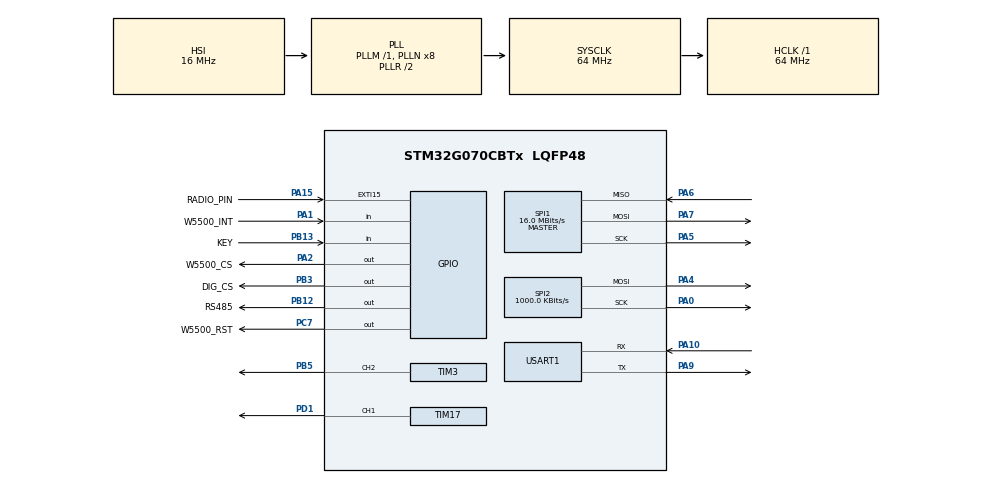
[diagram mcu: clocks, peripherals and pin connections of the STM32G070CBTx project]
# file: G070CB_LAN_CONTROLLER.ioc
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FREERTOS.BinarySemaphores01=SemSaveSettings,Static,mySemSaveSettingsControlBlock
FREERTOS.MEMORY_ALLOCATION=1
FREERTOS.Queues01=Periods,30,uint32_t,0,Static,PeriodsBuffer,PeriodsControlBlock;MQTT_Messages,10,MQTT_Packet,0,Static,MQTT_MessagesBuffer,MQTT_MessagesControlBlock;logQueue,200,unsigned char,0,Static,myQueue03Buffer,myQueue03ControlBlock;modbusQueue,5,uint64_t,0,Static,modbusQueue04Buffer,myQueue04ControlBlock
FREERTOS.Tasks01=defaultTask,-1,300,StartDefaultTask,As weak,NULL,Static,defaultTaskBuffer,defaultTaskControlBlock;LanTask,-1,400,StartLanTask,As weak,NULL,Static,LanTaskBuffer,LanTaskControlBlock;RadioReceiver,-3,200,StartRadioReceiver,As weak,NULL,Static,RadioReceiverBuffer,RadioReceiverControlBlock;ModBus,-1,300,modbus,As weak,NULL,Static,myTask04Buffer,myTask04ControlBlock;SaveSettings,3,128,SaveSettingsTask,As weak,NULL,Static,myTask05Buffer,myTask05ControlBlock
FREERTOS.Timers01=LED_INDICATION,led_indication,osTimerPeriodic,As weak,NULL,Static,LED_INDICATIONControlBlock;everySecond,everySecondCallback,osTimerPeriodic,As weak,NULL,Static,everySecondControlBlock;modBusTimer,ModBusCallback,osTimerPeriodic,As weak,NULL,Static,myTimer03ControlBlock
FREERTOS.configTOTAL_HEAP_SIZE=7000
FREERTOS.configUSE_NEWLIB_REENTRANT=1
FREERTOS.configUSE_TIMERS=1
FREERTOS.configUSE_TRACE_FACILITY=1
IWDG.Prescaler=IWDG_PRESCALER_256
Mcu.Family=STM32G0
Mcu.Name=STM32G070CBTx
Mcu.Package=LQFP48
NVIC.EXTI4_15_IRQn=true\:3\:0\:true\:false\:true\:false\:true\:true
NVIC.SPI1_IRQn=true\:3\:0\:false\:false\:true\:true\:true\:true
NVIC.TIM6_IRQn=true\:3\:0\:false\:false\:true\:false\:false\:true
NVIC.TimeBase=TIM6_IRQn
NVIC.TimeBaseIP=TIM6
PA0.Mode=TX_Only_Simplex_Unidirect_Master
PA0.Signal=SPI2_SCK
PA1.GPIO_Label=W5500_INT
PA1.Signal=GPIO_Input
PA10.Mode=Asynchronous
PA10.Signal=USART1_RX
PA13.Mode=Serial_Wire
PA13.Signal=SYS_SWDIO
PA14-BOOT0.Mode=Serial_Wire
PA14-BOOT0.Signal=SYS_SWCLK
PA15.GPIO_Label=RADIO_PIN
PA15.GPIO_ModeDefaultEXTI=GPIO_MODE_IT_RISING_FALLING
PA15.Signal=GPXTI15
PA2.GPIO_Label=W5500_CS
PA2.Signal=GPIO_Output
PA4.Mode=TX_Only_Simplex_Unidirect_Master
PA4.Signal=SPI2_MOSI
PA5.Mode=Full_Duplex_Master
PA5.Signal=SPI1_SCK
PA6.Mode=Full_Duplex_Master
PA6.Signal=SPI1_MISO
PA7.Mode=Full_Duplex_Master
PA7.Signal=SPI1_MOSI
PA9.Mode=Asynchronous
PA9.Signal=USART1_TX
PB12.GPIO_Label=RS485
PB12.Signal=GPIO_Output
PB13.GPIO_Label=KEY
PB13.Signal=GPIO_Input
PB3.GPIO_Label=DIG_CS
PB3.GPIO_Speed=GPIO_SPEED_FREQ_HIGH
PB3.PinState=GPIO_PIN_SET
PB3.Signal=GPIO_Output
PB5.Signal=S_TIM3_CH2
PB8.Signal=USART3_TX
PC7.GPIO_Label=W5500_RST
PC7.Signal=GPIO_Output
PD1.Signal=S_TIM17_CH1
ProjectManager.HeapSize=0x400
ProjectManager.StackSize=0x400
ProjectManager.TargetToolchain=STM32CubeIDE
RCC.ADCFreq_Value=64000000
RCC.AHBFreq_Value=64000000
RCC.CortexFreq_Value=64000000
RCC.EXTERNAL_CLOCK_VALUE=48000
RCC.HCLKFreq_Value=64000000
RCC.HSE_VALUE=8000000
RCC.HSI_VALUE=16000000
RCC.LSE_VALUE=32768
RCC.SYSCLKFreq_VALUE=64000000
RCC.SYSCLKSource=RCC_SYSCLKSOURCE_PLLCLK
RCC.VCOOutputFreq_Value=128000000
SH.S_TIM17_CH1.0=TIM17_CH1,PWM Generation1 CH1
SH.S_TIM3_CH2.0=TIM3_CH2,PWM Generation2 CH2
SPI1.BaudRatePrescaler=SPI_BAUDRATEPRESCALER_4
SPI1.CalculateBaudRate=16.0 MBits/s
SPI1.DataSize=SPI_DATASIZE_8BIT
SPI1.Direction=SPI_DIRECTION_2LINES
SPI1.Mode=SPI_MODE_MASTER
SPI1.VirtualType=VM_MASTER
SPI2.BaudRatePrescaler=SPI_BAUDRATEPRESCALER_64
SPI2.CalculateBaudRate=1000.0 KBits/s
SPI2.DataSize=SPI_DATASIZE_8BIT
SPI2.Direction=SPI_DIRECTION_2LINES
SPI2.Mode=SPI_MODE_MASTER
SPI2.VirtualType=VM_MASTER
TIM16.Prescaler=63
TIM17.Channel=TIM_CHANNEL_1
TIM17.OCIdleState_1=TIM_OCIDLESTATE_SET
TIM17.Period=1000
TIM17.Prescaler=10
TIM3.Channel-PWM\ Generation2\ CH2=TIM_CHANNEL_2
TIM3.Period=1000
TIM3.Prescaler=64
TIM3.Pulse-PWM\ Generation2\ CH2=0
USART1.BaudRate=system_settings.uart_speed
USART1.VirtualMode-Asynchronous=VM_ASYNC
VP_FREERTOS_VS_CMSIS_V1.Mode=CMSIS_V1
VP_IWDG_VS_IWDG.Mode=IWDG_Activate
VP_SYS_VS_DBSignals.Mode=DisableDeadBatterySignals
VP_SYS_VS_tim6.Mode=TIM6
VP_TIM16_VS_ClockSourceINT.Mode=Enable_Timer
VP_TIM17_VS_ClockSourceINT.Mode=Enable_Timer
VP_TIM3_VS_ClockSourceINT.Mode=Internal
board=custom

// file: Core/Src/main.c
/* USER CODE BEGIN Header */
/**
  ******************************************************************************
  * @file           : main.c
  * @brief          : Main program body
  ******************************************************************************
  * @attention
  *
  * Copyright (c) 2022 STMicroelectronics.
  * All rights reserved.
  *
  * This software is licensed under terms that can be found in the LICENSE file
  * in the root directory of this software component.
  * If no LICENSE file comes with this software, it is provided AS-IS.
  *
  ******************************************************************************
  */
/* USER CODE END Header */
#include "main.h"
#include "cmsis_os.h"
#include "iwdg.h"
#include "spi.h"
#include "tim.h"
#include "usart.h"
#include "gpio.h"

/* USER CODE BEGIN Includes */
#include "functions.h"
/* USER CODE END Includes */

/* USER CODE BEGIN PV */
extern dev_settings system_settings;
/* USER CODE END PV */

void SystemClock_Config(void);
void MX_FREERTOS_Init(void);

int main(void)
{

  /* MCU Configuration--------------------------------------------------------*/

  /* Reset of all peripherals, Initializes the Flash interface and the Systick. */
  HAL_Init();

  /* USER CODE BEGIN Init */
system_settings.uart_speed =9600;
  /* USER CODE END Init */

  /* Configure the system clock */
  SystemClock_Config();

  /* Initialize all configured peripherals */
  MX_GPIO_Init();
  MX_SPI1_Init();
  MX_SPI2_Init();
  MX_USART1_UART_Init();
  MX_TIM16_Init();
  MX_IWDG_Init();
  MX_TIM3_Init();
  MX_TIM17_Init();
  /* USER CODE BEGIN 2 */

  HAL_TIM_PWM_Start(&htim17, TIM_CHANNEL_1);

  /* USER CODE END 2 */

  /* Call init function for freertos objects (in freertos.c) */
  MX_FREERTOS_Init();
  /* Start scheduler */
  osKernelStart();

  /* We should never get here as control is now taken by the scheduler */
  /* Infinite loop */
  while (1)
  {

  }
}

void SystemClock_Config(void)
{
  RCC_OscInitTypeDef RCC_OscInitStruct = {0};
  RCC_ClkInitTypeDef RCC_ClkInitStruct = {0};

  /** Configure the main internal regulator output voltage
  */
  HAL_PWREx_ControlVoltageScaling(PWR_REGULATOR_VOLTAGE_SCALE1);
  /** Initializes the RCC Oscillators according to the specified parameters
  * in the RCC_OscInitTypeDef structure.
  */
  RCC_OscInitStruct.OscillatorType = RCC_OSCILLATORTYPE_HSI|RCC_OSCILLATORTYPE_LSI;
  RCC_OscInitStruct.HSIState = RCC_HSI_ON;
  RCC_OscInitStruct.HSIDiv = RCC_HSI_DIV1;
  RCC_OscInitStruct.HSICalibrationValue = RCC_HSICALIBRATION_DEFAULT;
  RCC_OscInitStruct.LSIState = RCC_LSI_ON;
  RCC_OscInitStruct.PLL.PLLState = RCC_PLL_ON;
  RCC_OscInitStruct.PLL.PLLSource = RCC_PLLSOURCE_HSI;
  RCC_OscInitStruct.PLL.PLLM = RCC_PLLM_DIV1;
  RCC_OscInitStruct.PLL.PLLN = 8;
  RCC_OscInitStruct.PLL.PLLP = RCC_PLLP_DIV2;
  RCC_OscInitStruct.PLL.PLLR = RCC_PLLR_DIV2;
  if (HAL_RCC_OscConfig(&RCC_OscInitStruct) != HAL_OK)
  {
    Error_Handler();
  }
  /** Initializes the CPU, AHB and APB buses clocks
  */
  RCC_ClkInitStruct.ClockType = RCC_CLOCKTYPE_HCLK|RCC_CLOCKTYPE_SYSCLK
                              |RCC_CLOCKTYPE_PCLK1;
  RCC_ClkInitStruct.SYSCLKSource = RCC_SYSCLKSOURCE_PLLCLK;
  RCC_ClkInitStruct.AHBCLKDivider = RCC_SYSCLK_DIV1;
  RCC_ClkInitStruct.APB1CLKDivider = RCC_HCLK_DIV1;

  if (HAL_RCC_ClockConfig(&RCC_ClkInitStruct, FLASH_LATENCY_2) != HAL_OK)
  {
    Error_Handler();
  }
}

void HAL_TIM_PeriodElapsedCallback(TIM_HandleTypeDef *htim)
{
  if (htim->Instance == TIM6) {
    HAL_IncTick();
  }
}

void Error_Handler(void)
{
  __disable_irq();
  while (1)
  {
  }
}

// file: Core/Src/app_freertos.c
/* USER CODE BEGIN Header */
/**
  ******************************************************************************
  * File Name          : app_freertos.c
  * Description        : Code for freertos applications
  ******************************************************************************
  * @attention
  *
  * Copyright (c) 2022 STMicroelectronics.
  * All rights reserved.
  *
  * This software is licensed under terms that can be found in the LICENSE file
  * in the root directory of this software component.
  * If no LICENSE file comes with this software, it is provided AS-IS.
  *
  ******************************************************************************
  */
/* USER CODE END Header */

#include "FreeRTOS.h"
#include "task.h"
#include "main.h"
#include "cmsis_os.h"

/* USER CODE BEGIN Includes */
#include "common.h"
/* USER CODE END Includes */

osThreadId defaultTaskHandle;
uint32_t defaultTaskBuffer[ 300 ];
osStaticThreadDef_t defaultTaskControlBlock;
osThreadId LanTaskHandle;
uint32_t LanTaskBuffer[ 400 ];
osStaticThreadDef_t LanTaskControlBlock;
osThreadId RadioReceiverHandle;
uint32_t RadioReceiverBuffer[ 200 ];
osStaticThreadDef_t RadioReceiverControlBlock;
osThreadId ModBusHandle;
uint32_t myTask04Buffer[ 300 ];
osStaticThreadDef_t myTask04ControlBlock;
osThreadId SaveSettingsHandle;
uint32_t myTask05Buffer[ 128 ];
osStaticThreadDef_t myTask05ControlBlock;
osMessageQId PeriodsHandle;
uint8_t PeriodsBuffer[ 30 * sizeof( uint32_t ) ];
osStaticMessageQDef_t PeriodsControlBlock;
osMessageQId MQTT_MessagesHandle;
uint8_t MQTT_MessagesBuffer[ 10 * sizeof( MQTT_Packet ) ];
osStaticMessageQDef_t MQTT_MessagesControlBlock;
osMessageQId logQueueHandle;
uint8_t myQueue03Buffer[ 200 * sizeof( unsigned char ) ];
osStaticMessageQDef_t myQueue03ControlBlock;
osMessageQId modbusQueueHandle;
uint8_t modbusQueue04Buffer[ 5 * sizeof( uint64_t ) ];
osStaticMessageQDef_t myQueue04ControlBlock;
osTimerId LED_INDICATIONHandle;
osStaticTimerDef_t LED_INDICATIONControlBlock;
osTimerId everySecondHandle;
osStaticTimerDef_t everySecondControlBlock;
osTimerId modBusTimerHandle;
osStaticTimerDef_t myTimer03ControlBlock;
osSemaphoreId SemSaveSettingsHandle;
osStaticSemaphoreDef_t mySemSaveSettingsControlBlock;

void StartDefaultTask(void const * argument);
void StartLanTask(void const * argument);
void StartRadioReceiver(void const * argument);
void modbus(void const * argument);
void SaveSettingsTask(void const * argument);
void led_indication(void const * argument);
void everySecondCallback(void const * argument);
void ModBusCallback(void const * argument);

void MX_FREERTOS_Init(void); /* (MISRA C 2004 rule 8.1) */

/* GetIdleTaskMemory prototype (linked to static allocation support) */
void vApplicationGetIdleTaskMemory( StaticTask_t **ppxIdleTaskTCBBuffer, StackType_t **ppxIdleTaskStackBuffer, uint32_t *pulIdleTaskStackSize );

/* GetTimerTaskMemory prototype (linked to static allocation support) */
void vApplicationGetTimerTaskMemory( StaticTask_t **ppxTimerTaskTCBBuffer, StackType_t **ppxTimerTaskStackBuffer, uint32_t *pulTimerTaskStackSize );

/* USER CODE BEGIN GET_IDLE_TASK_MEMORY */
static StaticTask_t xIdleTaskTCBBuffer;
static StackType_t xIdleStack[configMINIMAL_STACK_SIZE];

void vApplicationGetIdleTaskMemory( StaticTask_t **ppxIdleTaskTCBBuffer, StackType_t **ppxIdleTaskStackBuffer, uint32_t *pulIdleTaskStackSize )
{
  *ppxIdleTaskTCBBuffer = &xIdleTaskTCBBuffer;
  *ppxIdleTaskStackBuffer = &xIdleStack[0];
  *pulIdleTaskStackSize = configMINIMAL_STACK_SIZE;
  /* place for user code */
}
/* USER CODE END GET_IDLE_TASK_MEMORY */

/* USER CODE BEGIN GET_TIMER_TASK_MEMORY */
static StaticTask_t xTimerTaskTCBBuffer;
static StackType_t xTimerStack[configTIMER_TASK_STACK_DEPTH];

void vApplicationGetTimerTaskMemory( StaticTask_t **ppxTimerTaskTCBBuffer, StackType_t **ppxTimerTaskStackBuffer, uint32_t *pulTimerTaskStackSize )
{
  *ppxTimerTaskTCBBuffer = &xTimerTaskTCBBuffer;
  *ppxTimerTaskStackBuffer = &xTimerStack[0];
  *pulTimerTaskStackSize = configTIMER_TASK_STACK_DEPTH;
  /* place for user code */
}
/* USER CODE END GET_TIMER_TASK_MEMORY */

void MX_FREERTOS_Init(void) {

  /* Create the semaphores(s) */
  /* definition and creation of SemSaveSettings */
  osSemaphoreStaticDef(SemSaveSettings, &mySemSaveSettingsControlBlock);
  SemSaveSettingsHandle = osSemaphoreCreate(osSemaphore(SemSaveSettings), 1);

  /* Create the timer(s) */
  /* definition and creation of LED_INDICATION */
  osTimerStaticDef(LED_INDICATION, led_indication, &LED_INDICATIONControlBlock);
  LED_INDICATIONHandle = osTimerCreate(osTimer(LED_INDICATION), osTimerPeriodic, NULL);

  /* definition and creation of everySecond */
  osTimerStaticDef(everySecond, everySecondCallback, &everySecondControlBlock);
  everySecondHandle = osTimerCreate(osTimer(everySecond), osTimerPeriodic, NULL);

  /* definition and creation of modBusTimer */
  osTimerStaticDef(modBusTimer, ModBusCallback, &myTimer03ControlBlock);
  modBusTimerHandle = osTimerCreate(osTimer(modBusTimer), osTimerPeriodic, NULL);

  /* Create the queue(s) */
  /* definition and creation of Periods */
  osMessageQStaticDef(Periods, 30, uint32_t, PeriodsBuffer, &PeriodsControlBlock);
  PeriodsHandle = osMessageCreate(osMessageQ(Periods), NULL);

  /* definition and creation of MQTT_Messages */
  osMessageQStaticDef(MQTT_Messages, 10, MQTT_Packet, MQTT_MessagesBuffer, &MQTT_MessagesControlBlock);
  MQTT_MessagesHandle = osMessageCreate(osMessageQ(MQTT_Messages), NULL);

  /* definition and creation of logQueue */
  osMessageQStaticDef(logQueue, 200, unsigned char, myQueue03Buffer, &myQueue03ControlBlock);
  logQueueHandle = osMessageCreate(osMessageQ(logQueue), NULL);

  /* definition and creation of modbusQueue */
  osMessageQStaticDef(modbusQueue, 5, uint64_t, modbusQueue04Buffer, &myQueue04ControlBlock);
  modbusQueueHandle = osMessageCreate(osMessageQ(modbusQueue), NULL);

  /* Create the thread(s) */
  /* definition and creation of defaultTask */
  osThreadStaticDef(defaultTask, StartDefaultTask, osPriorityBelowNormal, 0, 300, defaultTaskBuffer, &defaultTaskControlBlock);
  defaultTaskHandle = osThreadCreate(osThread(defaultTask), NULL);

  /* definition and creation of LanTask */
  osThreadStaticDef(LanTask, StartLanTask, osPriorityBelowNormal, 0, 400, LanTaskBuffer, &LanTaskControlBlock);
  LanTaskHandle = osThreadCreate(osThread(LanTask), NULL);

  /* definition and creation of RadioReceiver */
  osThreadStaticDef(RadioReceiver, StartRadioReceiver, osPriorityIdle, 0, 200, RadioReceiverBuffer, &RadioReceiverControlBlock);
  RadioReceiverHandle = osThreadCreate(osThread(RadioReceiver), NULL);

  /* definition and creation of ModBus */
  osThreadStaticDef(ModBus, modbus, osPriorityBelowNormal, 0, 300, myTask04Buffer, &myTask04ControlBlock);
  ModBusHandle = osThreadCreate(osThread(ModBus), NULL);

  /* definition and creation of SaveSettings */
  osThreadStaticDef(SaveSettings, SaveSettingsTask, osPriorityRealtime, 0, 128, myTask05Buffer, &myTask05ControlBlock);
  SaveSettingsHandle = osThreadCreate(osThread(SaveSettings), NULL);

  /* USER CODE BEGIN RTOS_THREADS */
  /* add threads, ... */
  //
  osTimerStart(everySecondHandle, 1000);

  osTimerStart(LED_INDICATIONHandle, 50);

  /* USER CODE END RTOS_THREADS */

}

__weak void StartDefaultTask(void const * argument)
{
  for(;;)
  {
    osDelay(1);
  }
}

__weak void StartLanTask(void const * argument)
{
  for(;;)
  {
    osDelay(1);
  }
}

__weak void StartRadioReceiver(void const * argument)
{
  for(;;)
  {
    osDelay(1);
  }
}

__weak void modbus(void const * argument)
{
  for(;;)
  {
    osDelay(1);
  }
}

__weak void SaveSettingsTask(void const * argument)
{
  for(;;)
  {
    osDelay(1);
  }
}

/* led_indication function */
__weak void led_indication(void const * argument)
{
}

/* everySecondCallback function */
__weak void everySecondCallback(void const * argument)
{
}

/* ModBusCallback function */
__weak void ModBusCallback(void const * argument)
{
}
